[part 1 of 2: package /AUTOSAR_Dem/SwComponentTypes]
AUTOSAR XML (schema 4-2-2)
package /AUTOSAR_Dem/SwComponentTypes
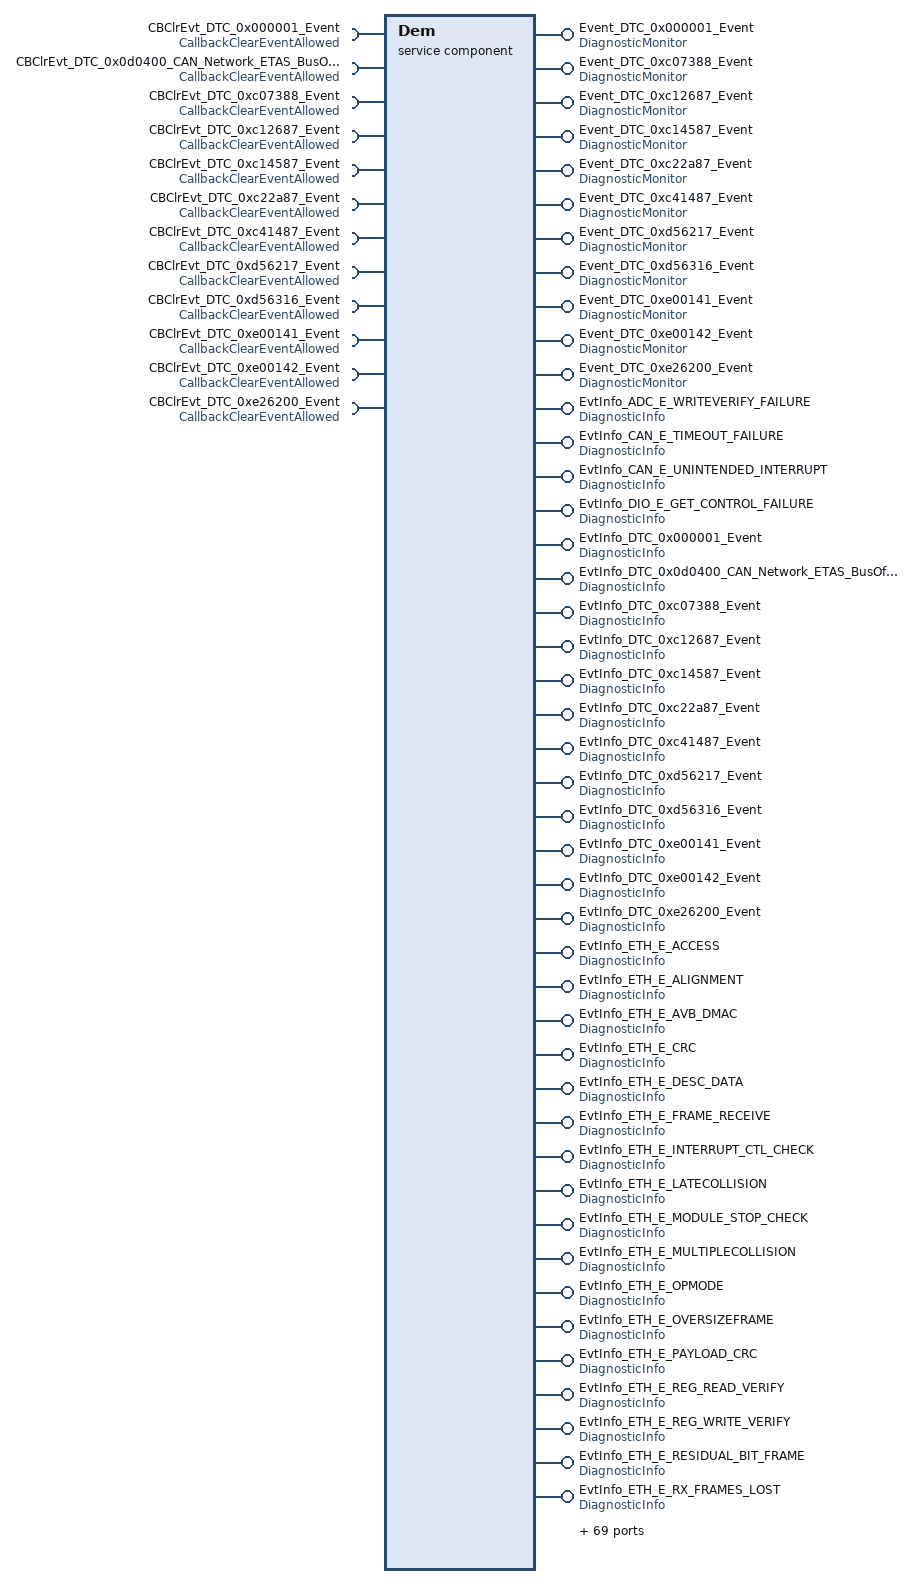
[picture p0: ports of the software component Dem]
  service sw component type Dem
    113 x provide port:
      Event_DTC_0x000001_Event: provided-interface=DiagnosticMonitor
        provided-com-specs:
          operation=SetEventStatus, queue-length=1
          operation=SetEventStatusWithEnvdata, queue-length=1
          operation=ResetEventStatus, queue-length=1
          operation=PrestoreFreezeFrame, queue-length=1
          operation=ClearPrestoredFreezeFrame, queue-length=1
          operation=ResetEventDebounceStatus, queue-length=1
      Event_DTC_0xc07388_Event: provided-interface=DiagnosticMonitor
        provided-com-specs:
          operation=SetEventStatus, queue-length=1
          operation=SetEventStatusWithEnvdata, queue-length=1
          operation=ResetEventStatus, queue-length=1
          operation=PrestoreFreezeFrame, queue-length=1
          operation=ClearPrestoredFreezeFrame, queue-length=1
          operation=ResetEventDebounceStatus, queue-length=1
      Event_DTC_0xc12687_Event: provided-interface=DiagnosticMonitor
        provided-com-specs:
          operation=SetEventStatus, queue-length=1
          operation=SetEventStatusWithEnvdata, queue-length=1
          operation=ResetEventStatus, queue-length=1
          operation=PrestoreFreezeFrame, queue-length=1
          operation=ClearPrestoredFreezeFrame, queue-length=1
          operation=ResetEventDebounceStatus, queue-length=1
      Event_DTC_0xc14587_Event: provided-interface=DiagnosticMonitor
        provided-com-specs:
          operation=SetEventStatus, queue-length=1
          operation=SetEventStatusWithEnvdata, queue-length=1
          operation=ResetEventStatus, queue-length=1
          operation=PrestoreFreezeFrame, queue-length=1
          operation=ClearPrestoredFreezeFrame, queue-length=1
          operation=ResetEventDebounceStatus, queue-length=1
      Event_DTC_0xc22a87_Event: provided-interface=DiagnosticMonitor
        provided-com-specs:
          operation=SetEventStatus, queue-length=1
          operation=SetEventStatusWithEnvdata, queue-length=1
          operation=ResetEventStatus, queue-length=1
          operation=PrestoreFreezeFrame, queue-length=1
          operation=ClearPrestoredFreezeFrame, queue-length=1
          operation=ResetEventDebounceStatus, queue-length=1
      Event_DTC_0xc41487_Event: provided-interface=DiagnosticMonitor
        provided-com-specs:
          operation=SetEventStatus, queue-length=1
          operation=SetEventStatusWithEnvdata, queue-length=1
          operation=ResetEventStatus, queue-length=1
          operation=PrestoreFreezeFrame, queue-length=1
          operation=ClearPrestoredFreezeFrame, queue-length=1
          operation=ResetEventDebounceStatus, queue-length=1
      Event_DTC_0xd56217_Event: provided-interface=DiagnosticMonitor
        provided-com-specs:
          operation=SetEventStatus, queue-length=1
          operation=SetEventStatusWithEnvdata, queue-length=1
          operation=ResetEventStatus, queue-length=1
          operation=PrestoreFreezeFrame, queue-length=1
          operation=ClearPrestoredFreezeFrame, queue-length=1
          operation=ResetEventDebounceStatus, queue-length=1
      Event_DTC_0xd56316_Event: provided-interface=DiagnosticMonitor
        provided-com-specs:
          operation=SetEventStatus, queue-length=1
          operation=SetEventStatusWithEnvdata, queue-length=1
          operation=ResetEventStatus, queue-length=1
          operation=PrestoreFreezeFrame, queue-length=1
          operation=ClearPrestoredFreezeFrame, queue-length=1
          operation=ResetEventDebounceStatus, queue-length=1
      Event_DTC_0xe00141_Event: provided-interface=DiagnosticMonitor
        provided-com-specs:
          operation=SetEventStatus, queue-length=1
          operation=SetEventStatusWithEnvdata, queue-length=1
          operation=ResetEventStatus, queue-length=1
          operation=PrestoreFreezeFrame, queue-length=1
          operation=ClearPrestoredFreezeFrame, queue-length=1
          operation=ResetEventDebounceStatus, queue-length=1
      Event_DTC_0xe00142_Event: provided-interface=DiagnosticMonitor
        provided-com-specs:
          operation=SetEventStatus, queue-length=1
          operation=SetEventStatusWithEnvdata, queue-length=1
          operation=ResetEventStatus, queue-length=1
          operation=PrestoreFreezeFrame, queue-length=1
          operation=ClearPrestoredFreezeFrame, queue-length=1
          operation=ResetEventDebounceStatus, queue-length=1
      Event_DTC_0xe26200_Event: provided-interface=DiagnosticMonitor
        provided-com-specs:
          operation=SetEventStatus, queue-length=1
          operation=SetEventStatusWithEnvdata, queue-length=1
          operation=ResetEventStatus, queue-length=1
          operation=PrestoreFreezeFrame, queue-length=1
          operation=ClearPrestoredFreezeFrame, queue-length=1
          operation=ResetEventDebounceStatus, queue-length=1
      EvtInfo_ADC_E_WRITEVERIFY_FAILURE: provided-interface=DiagnosticInfo
        provided-com-specs:
          operation=DiagnosticInfo/GetEventStatus, queue-length=1
          operation=DiagnosticInfo/GetEventFailed, queue-length=1
          operation=DiagnosticInfo/GetEventTested, queue-length=1
          operation=DiagnosticInfo/GetDTCOfEvent, queue-length=1
          operation=DiagnosticInfo/GetDebouncingOfEvent, queue-length=1
          operation=DiagnosticInfo/GetFaultDetectionCounter, queue-length=1
          operation=DiagnosticInfo/GetEventExtendedDataRecord, queue-length=1
          operation=DiagnosticInfo/GetEventExtendedDataRecordEx, queue-length=1
          operation=DiagnosticInfo/GetEventFreezeFrameData, queue-length=1
          operation=DiagnosticInfo/GetEventFreezeFrameDataEx, queue-length=1
      EvtInfo_CAN_E_TIMEOUT_FAILURE: provided-interface=DiagnosticInfo
        provided-com-specs:
          operation=DiagnosticInfo/GetEventStatus, queue-length=1
          operation=DiagnosticInfo/GetEventFailed, queue-length=1
          operation=DiagnosticInfo/GetEventTested, queue-length=1
          operation=DiagnosticInfo/GetDTCOfEvent, queue-length=1
          operation=DiagnosticInfo/GetDebouncingOfEvent, queue-length=1
          operation=DiagnosticInfo/GetFaultDetectionCounter, queue-length=1
          operation=DiagnosticInfo/GetEventExtendedDataRecord, queue-length=1
          operation=DiagnosticInfo/GetEventExtendedDataRecordEx, queue-length=1
          operation=DiagnosticInfo/GetEventFreezeFrameData, queue-length=1
          operation=DiagnosticInfo/GetEventFreezeFrameDataEx, queue-length=1
      EvtInfo_CAN_E_UNINTENDED_INTERRUPT: provided-interface=DiagnosticInfo
        provided-com-specs:
          operation=DiagnosticInfo/GetEventStatus, queue-length=1
          operation=DiagnosticInfo/GetEventFailed, queue-length=1
          operation=DiagnosticInfo/GetEventTested, queue-length=1
          operation=DiagnosticInfo/GetDTCOfEvent, queue-length=1
          operation=DiagnosticInfo/GetDebouncingOfEvent, queue-length=1
          operation=DiagnosticInfo/GetFaultDetectionCounter, queue-length=1
          operation=DiagnosticInfo/GetEventExtendedDataRecord, queue-length=1
          operation=DiagnosticInfo/GetEventExtendedDataRecordEx, queue-length=1
          operation=DiagnosticInfo/GetEventFreezeFrameData, queue-length=1
          operation=DiagnosticInfo/GetEventFreezeFrameDataEx, queue-length=1
      EvtInfo_DIO_E_GET_CONTROL_FAILURE: provided-interface=DiagnosticInfo
        provided-com-specs:
          operation=DiagnosticInfo/GetEventStatus, queue-length=1
          operation=DiagnosticInfo/GetEventFailed, queue-length=1
          operation=DiagnosticInfo/GetEventTested, queue-length=1
          operation=DiagnosticInfo/GetDTCOfEvent, queue-length=1
          operation=DiagnosticInfo/GetDebouncingOfEvent, queue-length=1
          operation=DiagnosticInfo/GetFaultDetectionCounter, queue-length=1
          operation=DiagnosticInfo/GetEventExtendedDataRecord, queue-length=1
          operation=DiagnosticInfo/GetEventExtendedDataRecordEx, queue-length=1
          operation=DiagnosticInfo/GetEventFreezeFrameData, queue-length=1
          operation=DiagnosticInfo/GetEventFreezeFrameDataEx, queue-length=1
      EvtInfo_DTC_0x000001_Event: provided-interface=DiagnosticInfo
        provided-com-specs:
          operation=DiagnosticInfo/GetEventStatus, queue-length=1
          operation=DiagnosticInfo/GetEventFailed, queue-length=1
          operation=DiagnosticInfo/GetEventTested, queue-length=1
          operation=DiagnosticInfo/GetDTCOfEvent, queue-length=1
          operation=DiagnosticInfo/GetDebouncingOfEvent, queue-length=1
          operation=DiagnosticInfo/GetFaultDetectionCounter, queue-length=1
          operation=DiagnosticInfo/GetEventExtendedDataRecord, queue-length=1
          operation=DiagnosticInfo/GetEventExtendedDataRecordEx, queue-length=1
          operation=DiagnosticInfo/GetEventFreezeFrameData, queue-length=1
          operation=DiagnosticInfo/GetEventFreezeFrameDataEx, queue-length=1
      EvtInfo_DTC_0x0d0400_CAN_Network_ETAS_BusOff_Event: provided-interface=DiagnosticInfo
        provided-com-specs:
          operation=DiagnosticInfo/GetEventStatus, queue-length=1
          operation=DiagnosticInfo/GetEventFailed, queue-length=1
          operation=DiagnosticInfo/GetEventTested, queue-length=1
          operation=DiagnosticInfo/GetDTCOfEvent, queue-length=1
          operation=DiagnosticInfo/GetDebouncingOfEvent, queue-length=1
          operation=DiagnosticInfo/GetFaultDetectionCounter, queue-length=1
          operation=DiagnosticInfo/GetEventExtendedDataRecord, queue-length=1
          operation=DiagnosticInfo/GetEventExtendedDataRecordEx, queue-length=1
          operation=DiagnosticInfo/GetEventFreezeFrameData, queue-length=1
          operation=DiagnosticInfo/GetEventFreezeFrameDataEx, queue-length=1
      EvtInfo_DTC_0xc07388_Event: provided-interface=DiagnosticInfo
        provided-com-specs:
          operation=DiagnosticInfo/GetEventStatus, queue-length=1
          operation=DiagnosticInfo/GetEventFailed, queue-length=1
          operation=DiagnosticInfo/GetEventTested, queue-length=1
          operation=DiagnosticInfo/GetDTCOfEvent, queue-length=1
          operation=DiagnosticInfo/GetDebouncingOfEvent, queue-length=1
          operation=DiagnosticInfo/GetFaultDetectionCounter, queue-length=1
          operation=DiagnosticInfo/GetEventExtendedDataRecord, queue-length=1
          operation=DiagnosticInfo/GetEventExtendedDataRecordEx, queue-length=1
          operation=DiagnosticInfo/GetEventFreezeFrameData, queue-length=1
          operation=DiagnosticInfo/GetEventFreezeFrameDataEx, queue-length=1
      EvtInfo_DTC_0xc12687_Event: provided-interface=DiagnosticInfo
        provided-com-specs:
          operation=DiagnosticInfo/GetEventStatus, queue-length=1
          operation=DiagnosticInfo/GetEventFailed, queue-length=1
          operation=DiagnosticInfo/GetEventTested, queue-length=1
          operation=DiagnosticInfo/GetDTCOfEvent, queue-length=1
          operation=DiagnosticInfo/GetDebouncingOfEvent, queue-length=1
          operation=DiagnosticInfo/GetFaultDetectionCounter, queue-length=1
          operation=DiagnosticInfo/GetEventExtendedDataRecord, queue-length=1
          operation=DiagnosticInfo/GetEventExtendedDataRecordEx, queue-length=1
          operation=DiagnosticInfo/GetEventFreezeFrameData, queue-length=1
          operation=DiagnosticInfo/GetEventFreezeFrameDataEx, queue-length=1
      EvtInfo_DTC_0xc14587_Event: provided-interface=DiagnosticInfo
        provided-com-specs:
          operation=DiagnosticInfo/GetEventStatus, queue-length=1
          operation=DiagnosticInfo/GetEventFailed, queue-length=1
          operation=DiagnosticInfo/GetEventTested, queue-length=1
          operation=DiagnosticInfo/GetDTCOfEvent, queue-length=1
          operation=DiagnosticInfo/GetDebouncingOfEvent, queue-length=1
          operation=DiagnosticInfo/GetFaultDetectionCounter, queue-length=1
          operation=DiagnosticInfo/GetEventExtendedDataRecord, queue-length=1
          operation=DiagnosticInfo/GetEventExtendedDataRecordEx, queue-length=1
          operation=DiagnosticInfo/GetEventFreezeFrameData, queue-length=1
          operation=DiagnosticInfo/GetEventFreezeFrameDataEx, queue-length=1
      EvtInfo_DTC_0xc22a87_Event: provided-interface=DiagnosticInfo
        provided-com-specs:
          operation=DiagnosticInfo/GetEventStatus, queue-length=1
          operation=DiagnosticInfo/GetEventFailed, queue-length=1
          operation=DiagnosticInfo/GetEventTested, queue-length=1
          operation=DiagnosticInfo/GetDTCOfEvent, queue-length=1
          operation=DiagnosticInfo/GetDebouncingOfEvent, queue-length=1
          operation=DiagnosticInfo/GetFaultDetectionCounter, queue-length=1
          operation=DiagnosticInfo/GetEventExtendedDataRecord, queue-length=1
          operation=DiagnosticInfo/GetEventExtendedDataRecordEx, queue-length=1
          operation=DiagnosticInfo/GetEventFreezeFrameData, queue-length=1
          operation=DiagnosticInfo/GetEventFreezeFrameDataEx, queue-length=1
      EvtInfo_DTC_0xc41487_Event: provided-interface=DiagnosticInfo
        provided-com-specs:
          operation=DiagnosticInfo/GetEventStatus, queue-length=1
          operation=DiagnosticInfo/GetEventFailed, queue-length=1
          operation=DiagnosticInfo/GetEventTested, queue-length=1
          operation=DiagnosticInfo/GetDTCOfEvent, queue-length=1
          operation=DiagnosticInfo/GetDebouncingOfEvent, queue-length=1
          operation=DiagnosticInfo/GetFaultDetectionCounter, queue-length=1
          operation=DiagnosticInfo/GetEventExtendedDataRecord, queue-length=1
          operation=DiagnosticInfo/GetEventExtendedDataRecordEx, queue-length=1
          operation=DiagnosticInfo/GetEventFreezeFrameData, queue-length=1
          operation=DiagnosticInfo/GetEventFreezeFrameDataEx, queue-length=1
      EvtInfo_DTC_0xd56217_Event: provided-interface=DiagnosticInfo
        provided-com-specs:
          operation=DiagnosticInfo/GetEventStatus, queue-length=1
          operation=DiagnosticInfo/GetEventFailed, queue-length=1
          operation=DiagnosticInfo/GetEventTested, queue-length=1
          operation=DiagnosticInfo/GetDTCOfEvent, queue-length=1
          operation=DiagnosticInfo/GetDebouncingOfEvent, queue-length=1
          operation=DiagnosticInfo/GetFaultDetectionCounter, queue-length=1
          operation=DiagnosticInfo/GetEventExtendedDataRecord, queue-length=1
          operation=DiagnosticInfo/GetEventExtendedDataRecordEx, queue-length=1
          operation=DiagnosticInfo/GetEventFreezeFrameData, queue-length=1
          operation=DiagnosticInfo/GetEventFreezeFrameDataEx, queue-length=1
      EvtInfo_DTC_0xd56316_Event: provided-interface=DiagnosticInfo
        provided-com-specs:
          operation=DiagnosticInfo/GetEventStatus, queue-length=1
          operation=DiagnosticInfo/GetEventFailed, queue-length=1
          operation=DiagnosticInfo/GetEventTested, queue-length=1
          operation=DiagnosticInfo/GetDTCOfEvent, queue-length=1
          operation=DiagnosticInfo/GetDebouncingOfEvent, queue-length=1
          operation=DiagnosticInfo/GetFaultDetectionCounter, queue-length=1
          operation=DiagnosticInfo/GetEventExtendedDataRecord, queue-length=1
          operation=DiagnosticInfo/GetEventExtendedDataRecordEx, queue-length=1
          operation=DiagnosticInfo/GetEventFreezeFrameData, queue-length=1
          operation=DiagnosticInfo/GetEventFreezeFrameDataEx, queue-length=1
      EvtInfo_DTC_0xe00141_Event: provided-interface=DiagnosticInfo
        provided-com-specs:
          operation=DiagnosticInfo/GetEventStatus, queue-length=1
          operation=DiagnosticInfo/GetEventFailed, queue-length=1
          operation=DiagnosticInfo/GetEventTested, queue-length=1
          operation=DiagnosticInfo/GetDTCOfEvent, queue-length=1
          operation=DiagnosticInfo/GetDebouncingOfEvent, queue-length=1
          operation=DiagnosticInfo/GetFaultDetectionCounter, queue-length=1
          operation=DiagnosticInfo/GetEventExtendedDataRecord, queue-length=1
          operation=DiagnosticInfo/GetEventExtendedDataRecordEx, queue-length=1
          operation=DiagnosticInfo/GetEventFreezeFrameData, queue-length=1
          operation=DiagnosticInfo/GetEventFreezeFrameDataEx, queue-length=1
      EvtInfo_DTC_0xe00142_Event: provided-interface=DiagnosticInfo
        provided-com-specs:
          operation=DiagnosticInfo/GetEventStatus, queue-length=1
          operation=DiagnosticInfo/GetEventFailed, queue-length=1
          operation=DiagnosticInfo/GetEventTested, queue-length=1
          operation=DiagnosticInfo/GetDTCOfEvent, queue-length=1
          operation=DiagnosticInfo/GetDebouncingOfEvent, queue-length=1
          operation=DiagnosticInfo/GetFaultDetectionCounter, queue-length=1
          operation=DiagnosticInfo/GetEventExtendedDataRecord, queue-length=1
          operation=DiagnosticInfo/GetEventExtendedDataRecordEx, queue-length=1
          operation=DiagnosticInfo/GetEventFreezeFrameData, queue-length=1
          operation=DiagnosticInfo/GetEventFreezeFrameDataEx, queue-length=1
      EvtInfo_DTC_0xe26200_Event: provided-interface=DiagnosticInfo
        provided-com-specs:
          operation=DiagnosticInfo/GetEventStatus, queue-length=1
          operation=DiagnosticInfo/GetEventFailed, queue-length=1
          operation=DiagnosticInfo/GetEventTested, queue-length=1
          operation=DiagnosticInfo/GetDTCOfEvent, queue-length=1
          operation=DiagnosticInfo/GetDebouncingOfEvent, queue-length=1
          operation=DiagnosticInfo/GetFaultDetectionCounter, queue-length=1
          operation=DiagnosticInfo/GetEventExtendedDataRecord, queue-length=1
          operation=DiagnosticInfo/GetEventExtendedDataRecordEx, queue-length=1
          operation=DiagnosticInfo/GetEventFreezeFrameData, queue-length=1
          operation=DiagnosticInfo/GetEventFreezeFrameDataEx, queue-length=1
      EvtInfo_ETH_E_ACCESS: provided-interface=DiagnosticInfo
        provided-com-specs:
          operation=DiagnosticInfo/GetEventStatus, queue-length=1
          operation=DiagnosticInfo/GetEventFailed, queue-length=1
          operation=DiagnosticInfo/GetEventTested, queue-length=1
          operation=DiagnosticInfo/GetDTCOfEvent, queue-length=1
          operation=DiagnosticInfo/GetDebouncingOfEvent, queue-length=1
          operation=DiagnosticInfo/GetFaultDetectionCounter, queue-length=1
          operation=DiagnosticInfo/GetEventExtendedDataRecord, queue-length=1
          operation=DiagnosticInfo/GetEventExtendedDataRecordEx, queue-length=1
          operation=DiagnosticInfo/GetEventFreezeFrameData, queue-length=1
          operation=DiagnosticInfo/GetEventFreezeFrameDataEx, queue-length=1
      EvtInfo_ETH_E_ALIGNMENT: provided-interface=DiagnosticInfo
        provided-com-specs:
          operation=DiagnosticInfo/GetEventStatus, queue-length=1
          operation=DiagnosticInfo/GetEventFailed, queue-length=1
          operation=DiagnosticInfo/GetEventTested, queue-length=1
          operation=DiagnosticInfo/GetDTCOfEvent, queue-length=1
          operation=DiagnosticInfo/GetDebouncingOfEvent, queue-length=1
          operation=DiagnosticInfo/GetFaultDetectionCounter, queue-length=1
          operation=DiagnosticInfo/GetEventExtendedDataRecord, queue-length=1
          operation=DiagnosticInfo/GetEventExtendedDataRecordEx, queue-length=1
          operation=DiagnosticInfo/GetEventFreezeFrameData, queue-length=1
          operation=DiagnosticInfo/GetEventFreezeFrameDataEx, queue-length=1
      EvtInfo_ETH_E_AVB_DMAC: provided-interface=DiagnosticInfo
        provided-com-specs:
          operation=DiagnosticInfo/GetEventStatus, queue-length=1
          operation=DiagnosticInfo/GetEventFailed, queue-length=1
          operation=DiagnosticInfo/GetEventTested, queue-length=1
          operation=DiagnosticInfo/GetDTCOfEvent, queue-length=1
          operation=DiagnosticInfo/GetDebouncingOfEvent, queue-length=1
          operation=DiagnosticInfo/GetFaultDetectionCounter, queue-length=1
          operation=DiagnosticInfo/GetEventExtendedDataRecord, queue-length=1
          operation=DiagnosticInfo/GetEventExtendedDataRecordEx, queue-length=1
          operation=DiagnosticInfo/GetEventFreezeFrameData, queue-length=1
          operation=DiagnosticInfo/GetEventFreezeFrameDataEx, queue-length=1
      EvtInfo_ETH_E_CRC: provided-interface=DiagnosticInfo
        provided-com-specs:
          operation=DiagnosticInfo/GetEventStatus, queue-length=1
          operation=DiagnosticInfo/GetEventFailed, queue-length=1
          operation=DiagnosticInfo/GetEventTested, queue-length=1
          operation=DiagnosticInfo/GetDTCOfEvent, queue-length=1
          operation=DiagnosticInfo/GetDebouncingOfEvent, queue-length=1
          operation=DiagnosticInfo/GetFaultDetectionCounter, queue-length=1
          operation=DiagnosticInfo/GetEventExtendedDataRecord, queue-length=1
          operation=DiagnosticInfo/GetEventExtendedDataRecordEx, queue-length=1
          operation=DiagnosticInfo/GetEventFreezeFrameData, queue-length=1
          operation=DiagnosticInfo/GetEventFreezeFrameDataEx, queue-length=1
      EvtInfo_ETH_E_DESC_DATA: provided-interface=DiagnosticInfo
        provided-com-specs:
          operation=DiagnosticInfo/GetEventStatus, queue-length=1
          operation=DiagnosticInfo/GetEventFailed, queue-length=1
          operation=DiagnosticInfo/GetEventTested, queue-length=1
          operation=DiagnosticInfo/GetDTCOfEvent, queue-length=1
          operation=DiagnosticInfo/GetDebouncingOfEvent, queue-length=1
          operation=DiagnosticInfo/GetFaultDetectionCounter, queue-length=1
          operation=DiagnosticInfo/GetEventExtendedDataRecord, queue-length=1
          operation=DiagnosticInfo/GetEventExtendedDataRecordEx, queue-length=1
          operation=DiagnosticInfo/GetEventFreezeFrameData, queue-length=1
          operation=DiagnosticInfo/GetEventFreezeFrameDataEx, queue-length=1
      EvtInfo_ETH_E_FRAME_RECEIVE: provided-interface=DiagnosticInfo
        provided-com-specs:
          operation=DiagnosticInfo/GetEventStatus, queue-length=1
          operation=DiagnosticInfo/GetEventFailed, queue-length=1
          operation=DiagnosticInfo/GetEventTested, queue-length=1
          operation=DiagnosticInfo/GetDTCOfEvent, queue-length=1
          operation=DiagnosticInfo/GetDebouncingOfEvent, queue-length=1
          operation=DiagnosticInfo/GetFaultDetectionCounter, queue-length=1
          operation=DiagnosticInfo/GetEventExtendedDataRecord, queue-length=1
          operation=DiagnosticInfo/GetEventExtendedDataRecordEx, queue-length=1
          operation=DiagnosticInfo/GetEventFreezeFrameData, queue-length=1
          operation=DiagnosticInfo/GetEventFreezeFrameDataEx, queue-length=1
      EvtInfo_ETH_E_INTERRUPT_CTL_CHECK: provided-interface=DiagnosticInfo
        provided-com-specs:
          operation=DiagnosticInfo/GetEventStatus, queue-length=1
          operation=DiagnosticInfo/GetEventFailed, queue-length=1
          operation=DiagnosticInfo/GetEventTested, queue-length=1
          operation=DiagnosticInfo/GetDTCOfEvent, queue-length=1
          operation=DiagnosticInfo/GetDebouncingOfEvent, queue-length=1
          operation=DiagnosticInfo/GetFaultDetectionCounter, queue-length=1
          operation=DiagnosticInfo/GetEventExtendedDataRecord, queue-length=1
          operation=DiagnosticInfo/GetEventExtendedDataRecordEx, queue-length=1
          operation=DiagnosticInfo/GetEventFreezeFrameData, queue-length=1
          operation=DiagnosticInfo/GetEventFreezeFrameDataEx, queue-length=1
      EvtInfo_ETH_E_LATECOLLISION: provided-interface=DiagnosticInfo
        provided-com-specs:
          operation=DiagnosticInfo/GetEventStatus, queue-length=1
          operation=DiagnosticInfo/GetEventFailed, queue-length=1
          operation=DiagnosticInfo/GetEventTested, queue-length=1
          operation=DiagnosticInfo/GetDTCOfEvent, queue-length=1
          operation=DiagnosticInfo/GetDebouncingOfEvent, queue-length=1
          operation=DiagnosticInfo/GetFaultDetectionCounter, queue-length=1
          operation=DiagnosticInfo/GetEventExtendedDataRecord, queue-length=1
          operation=DiagnosticInfo/GetEventExtendedDataRecordEx, queue-length=1
          operation=DiagnosticInfo/GetEventFreezeFrameData, queue-length=1
          operation=DiagnosticInfo/GetEventFreezeFrameDataEx, queue-length=1
      EvtInfo_ETH_E_MODULE_STOP_CHECK: provided-interface=DiagnosticInfo
        provided-com-specs:
          operation=DiagnosticInfo/GetEventStatus, queue-length=1
          operation=DiagnosticInfo/GetEventFailed, queue-length=1
          operation=DiagnosticInfo/GetEventTested, queue-length=1
          operation=DiagnosticInfo/GetDTCOfEvent, queue-length=1
          operation=DiagnosticInfo/GetDebouncingOfEvent, queue-length=1
          operation=DiagnosticInfo/GetFaultDetectionCounter, queue-length=1
          operation=DiagnosticInfo/GetEventExtendedDataRecord, queue-length=1
          operation=DiagnosticInfo/GetEventExtendedDataRecordEx, queue-length=1
          operation=DiagnosticInfo/GetEventFreezeFrameData, queue-length=1
          operation=DiagnosticInfo/GetEventFreezeFrameDataEx, queue-length=1
      EvtInfo_ETH_E_MULTIPLECOLLISION: provided-interface=DiagnosticInfo
        provided-com-specs:
          operation=DiagnosticInfo/GetEventStatus, queue-length=1
          operation=DiagnosticInfo/GetEventFailed, queue-length=1
          operation=DiagnosticInfo/GetEventTested, queue-length=1
          operation=DiagnosticInfo/GetDTCOfEvent, queue-length=1
          operation=DiagnosticInfo/GetDebouncingOfEvent, queue-length=1
          operation=DiagnosticInfo/GetFaultDetectionCounter, queue-length=1
          operation=DiagnosticInfo/GetEventExtendedDataRecord, queue-length=1
          operation=DiagnosticInfo/GetEventExtendedDataRecordEx, queue-length=1
          operation=DiagnosticInfo/GetEventFreezeFrameData, queue-length=1
          operation=DiagnosticInfo/GetEventFreezeFrameDataEx, queue-length=1
      EvtInfo_ETH_E_OPMODE: provided-interface=DiagnosticInfo
        provided-com-specs:
          operation=DiagnosticInfo/GetEventStatus, queue-length=1
          operation=DiagnosticInfo/GetEventFailed, queue-length=1
          operation=DiagnosticInfo/GetEventTested, queue-length=1
          operation=DiagnosticInfo/GetDTCOfEvent, queue-length=1
          operation=DiagnosticInfo/GetDebouncingOfEvent, queue-length=1
          operation=DiagnosticInfo/GetFaultDetectionCounter, queue-length=1
          operation=DiagnosticInfo/GetEventExtendedDataRecord, queue-length=1
          operation=DiagnosticInfo/GetEventExtendedDataRecordEx, queue-length=1
          operation=DiagnosticInfo/GetEventFreezeFrameData, queue-length=1
          operation=DiagnosticInfo/GetEventFreezeFrameDataEx, queue-length=1
      EvtInfo_ETH_E_OVERSIZEFRAME: provided-interface=DiagnosticInfo
        provided-com-specs:
          operation=DiagnosticInfo/GetEventStatus, queue-length=1
          operation=DiagnosticInfo/GetEventFailed, queue-length=1
          operation=DiagnosticInfo/GetEventTested, queue-length=1
          operation=DiagnosticInfo/GetDTCOfEvent, queue-length=1
          operation=DiagnosticInfo/GetDebouncingOfEvent, queue-length=1
          operation=DiagnosticInfo/GetFaultDetectionCounter, queue-length=1
          operation=DiagnosticInfo/GetEventExtendedDataRecord, queue-length=1
          operation=DiagnosticInfo/GetEventExtendedDataRecordEx, queue-length=1
          operation=DiagnosticInfo/GetEventFreezeFrameData, queue-length=1
          operation=DiagnosticInfo/GetEventFreezeFrameDataEx, queue-length=1
      EvtInfo_ETH_E_PAYLOAD_CRC: provided-interface=DiagnosticInfo
        provided-com-specs:
          operation=DiagnosticInfo/GetEventStatus, queue-length=1
          operation=DiagnosticInfo/GetEventFailed, queue-length=1
          operation=DiagnosticInfo/GetEventTested, queue-length=1
          operation=DiagnosticInfo/GetDTCOfEvent, queue-length=1
          operation=DiagnosticInfo/GetDebouncingOfEvent, queue-length=1
          operation=DiagnosticInfo/GetFaultDetectionCounter, queue-length=1
          operation=DiagnosticInfo/GetEventExtendedDataRecord, queue-length=1
          operation=DiagnosticInfo/GetEventExtendedDataRecordEx, queue-length=1
          operation=DiagnosticInfo/GetEventFreezeFrameData, queue-length=1
          operation=DiagnosticInfo/GetEventFreezeFrameDataEx, queue-length=1
      EvtInfo_ETH_E_REG_READ_VERIFY: provided-interface=DiagnosticInfo
        provided-com-specs:
          operation=DiagnosticInfo/GetEventStatus, queue-length=1
          operation=DiagnosticInfo/GetEventFailed, queue-length=1
          operation=DiagnosticInfo/GetEventTested, queue-length=1
          operation=DiagnosticInfo/GetDTCOfEvent, queue-length=1
          operation=DiagnosticInfo/GetDebouncingOfEvent, queue-length=1
          operation=DiagnosticInfo/GetFaultDetectionCounter, queue-length=1
          operation=DiagnosticInfo/GetEventExtendedDataRecord, queue-length=1
          operation=DiagnosticInfo/GetEventExtendedDataRecordEx, queue-length=1
          operation=DiagnosticInfo/GetEventFreezeFrameData, queue-length=1
          operation=DiagnosticInfo/GetEventFreezeFrameDataEx, queue-length=1
      EvtInfo_ETH_E_REG_WRITE_VERIFY: provided-interface=DiagnosticInfo
        provided-com-specs:
          operation=DiagnosticInfo/GetEventStatus, queue-length=1
          operation=DiagnosticInfo/GetEventFailed, queue-length=1
          operation=DiagnosticInfo/GetEventTested, queue-length=1
          operation=DiagnosticInfo/GetDTCOfEvent, queue-length=1
          operation=DiagnosticInfo/GetDebouncingOfEvent, queue-length=1
          operation=DiagnosticInfo/GetFaultDetectionCounter, queue-length=1
          operation=DiagnosticInfo/GetEventExtendedDataRecord, queue-length=1
          operation=DiagnosticInfo/GetEventExtendedDataRecordEx, queue-length=1
          operation=DiagnosticInfo/GetEventFreezeFrameData, queue-length=1
          operation=DiagnosticInfo/GetEventFreezeFrameDataEx, queue-length=1
      EvtInfo_ETH_E_RESIDUAL_BIT_FRAME: provided-interface=DiagnosticInfo
        provided-com-specs:
          operation=DiagnosticInfo/GetEventStatus, queue-length=1
          operation=DiagnosticInfo/GetEventFailed, queue-length=1
          operation=DiagnosticInfo/GetEventTested, queue-length=1
          operation=DiagnosticInfo/GetDTCOfEvent, queue-length=1
          operation=DiagnosticInfo/GetDebouncingOfEvent, queue-length=1
          operation=DiagnosticInfo/GetFaultDetectionCounter, queue-length=1
          operation=DiagnosticInfo/GetEventExtendedDataRecord, queue-length=1
          operation=DiagnosticInfo/GetEventExtendedDataRecordEx, queue-length=1
          operation=DiagnosticInfo/GetEventFreezeFrameData, queue-length=1
          operation=DiagnosticInfo/GetEventFreezeFrameDataEx, queue-length=1
      EvtInfo_ETH_E_RX_FRAMES_LOST: provided-interface=DiagnosticInfo
        provided-com-specs:
          operation=DiagnosticInfo/GetEventStatus, queue-length=1
          operation=DiagnosticInfo/GetEventFailed, queue-length=1
          operation=DiagnosticInfo/GetEventTested, queue-length=1
          operation=DiagnosticInfo/GetDTCOfEvent, queue-length=1
          operation=DiagnosticInfo/GetDebouncingOfEvent, queue-length=1
          operation=DiagnosticInfo/GetFaultDetectionCounter, queue-length=1
          operation=DiagnosticInfo/GetEventExtendedDataRecord, queue-length=1
          operation=DiagnosticInfo/GetEventExtendedDataRecordEx, queue-length=1
          operation=DiagnosticInfo/GetEventFreezeFrameData, queue-length=1
          operation=DiagnosticInfo/GetEventFreezeFrameDataEx, queue-length=1
      EvtInfo_ETH_E_SINGLECOLLISION: provided-interface=DiagnosticInfo
        provided-com-specs:
          operation=DiagnosticInfo/GetEventStatus, queue-length=1
          operation=DiagnosticInfo/GetEventFailed, queue-length=1
          operation=DiagnosticInfo/GetEventTested, queue-length=1
          operation=DiagnosticInfo/GetDTCOfEvent, queue-length=1
          operation=DiagnosticInfo/GetDebouncingOfEvent, queue-length=1
          operation=DiagnosticInfo/GetFaultDetectionCounter, queue-length=1
          operation=DiagnosticInfo/GetEventExtendedDataRecord, queue-length=1
          operation=DiagnosticInfo/GetEventExtendedDataRecordEx, queue-length=1
          operation=DiagnosticInfo/GetEventFreezeFrameData, queue-length=1
          operation=DiagnosticInfo/GetEventFreezeFrameDataEx, queue-length=1
      EvtInfo_ETH_E_TIMEOUT: provided-interface=DiagnosticInfo
        provided-com-specs:
          operation=DiagnosticInfo/GetEventStatus, queue-length=1
          operation=DiagnosticInfo/GetEventFailed, queue-length=1
          operation=DiagnosticInfo/GetEventTested, queue-length=1
          operation=DiagnosticInfo/GetDTCOfEvent, queue-length=1
          operation=DiagnosticInfo/GetDebouncingOfEvent, queue-length=1
          operation=DiagnosticInfo/GetFaultDetectionCounter, queue-length=1
          operation=DiagnosticInfo/GetEventExtendedDataRecord, queue-length=1
          operation=DiagnosticInfo/GetEventExtendedDataRecordEx, queue-length=1
          operation=DiagnosticInfo/GetEventFreezeFrameData, queue-length=1
          operation=DiagnosticInfo/GetEventFreezeFrameDataEx, queue-length=1
      EvtInfo_ETH_E_TIMERINC_FAILED: provided-interface=DiagnosticInfo
        provided-com-specs:
          operation=DiagnosticInfo/GetEventStatus, queue-length=1
          operation=DiagnosticInfo/GetEventFailed, queue-length=1
          operation=DiagnosticInfo/GetEventTested, queue-length=1
          operation=DiagnosticInfo/GetDTCOfEvent, queue-length=1
          operation=DiagnosticInfo/GetDebouncingOfEvent, queue-length=1
          operation=DiagnosticInfo/GetFaultDetectionCounter, queue-length=1
          operation=DiagnosticInfo/GetEventExtendedDataRecord, queue-length=1
          operation=DiagnosticInfo/GetEventExtendedDataRecordEx, queue-length=1
          operation=DiagnosticInfo/GetEventFreezeFrameData, queue-length=1
          operation=DiagnosticInfo/GetEventFreezeFrameDataEx, queue-length=1
      EvtInfo_ETH_E_TRANSMIT_RETRY_OVER: provided-interface=DiagnosticInfo
        provided-com-specs:
          operation=DiagnosticInfo/GetEventStatus, queue-length=1
          operation=DiagnosticInfo/GetEventFailed, queue-length=1
          operation=DiagnosticInfo/GetEventTested, queue-length=1
          operation=DiagnosticInfo/GetDTCOfEvent, queue-length=1
          operation=DiagnosticInfo/GetDebouncingOfEvent, queue-length=1
          operation=DiagnosticInfo/GetFaultDetectionCounter, queue-length=1
          operation=DiagnosticInfo/GetEventExtendedDataRecord, queue-length=1
          operation=DiagnosticInfo/GetEventExtendedDataRecordEx, queue-length=1
          operation=DiagnosticInfo/GetEventFreezeFrameData, queue-length=1
          operation=DiagnosticInfo/GetEventFreezeFrameDataEx, queue-length=1
      EvtInfo_ETH_E_UNDERSIZEFRAME: provided-interface=DiagnosticInfo
        provided-com-specs:
          operation=DiagnosticInfo/GetEventStatus, queue-length=1
          operation=DiagnosticInfo/GetEventFailed, queue-length=1
          operation=DiagnosticInfo/GetEventTested, queue-length=1
          operation=DiagnosticInfo/GetDTCOfEvent, queue-length=1
          operation=DiagnosticInfo/GetDebouncingOfEvent, queue-length=1
          operation=DiagnosticInfo/GetFaultDetectionCounter, queue-length=1
          operation=DiagnosticInfo/GetEventExtendedDataRecord, queue-length=1
          operation=DiagnosticInfo/GetEventExtendedDataRecordEx, queue-length=1
          operation=DiagnosticInfo/GetEventFreezeFrameData, queue-length=1
          operation=DiagnosticInfo/GetEventFreezeFrameDataEx, queue-length=1
      EvtInfo_FLS_E_COMPARE_FAILED: provided-interface=DiagnosticInfo
        provided-com-specs:
          operation=DiagnosticInfo/GetEventStatus, queue-length=1
          operation=DiagnosticInfo/GetEventFailed, queue-length=1
          operation=DiagnosticInfo/GetEventTested, queue-length=1
          operation=DiagnosticInfo/GetDTCOfEvent, queue-length=1
          operation=DiagnosticInfo/GetDebouncingOfEvent, queue-length=1
          operation=DiagnosticInfo/GetFaultDetectionCounter, queue-length=1
          operation=DiagnosticInfo/GetEventExtendedDataRecord, queue-length=1
          operation=DiagnosticInfo/GetEventExtendedDataRecordEx, queue-length=1
          operation=DiagnosticInfo/GetEventFreezeFrameData, queue-length=1
          operation=DiagnosticInfo/GetEventFreezeFrameDataEx, queue-length=1
      EvtInfo_FLS_E_ERASE_FAILED: provided-interface=DiagnosticInfo
        provided-com-specs:
          operation=DiagnosticInfo/GetEventStatus, queue-length=1
          operation=DiagnosticInfo/GetEventFailed, queue-length=1
          operation=DiagnosticInfo/GetEventTested, queue-length=1
          operation=DiagnosticInfo/GetDTCOfEvent, queue-length=1
          operation=DiagnosticInfo/GetDebouncingOfEvent, queue-length=1
          operation=DiagnosticInfo/GetFaultDetectionCounter, queue-length=1
          operation=DiagnosticInfo/GetEventExtendedDataRecord, queue-length=1
          operation=DiagnosticInfo/GetEventExtendedDataRecordEx, queue-length=1
          operation=DiagnosticInfo/GetEventFreezeFrameData, queue-length=1
          operation=DiagnosticInfo/GetEventFreezeFrameDataEx, queue-length=1
      EvtInfo_FLS_E_GET_CONTROL_FAILURE: provided-interface=DiagnosticInfo
        provided-com-specs:
          operation=DiagnosticInfo/GetEventStatus, queue-length=1
          operation=DiagnosticInfo/GetEventFailed, queue-length=1
          operation=DiagnosticInfo/GetEventTested, queue-length=1
          operation=DiagnosticInfo/GetDTCOfEvent, queue-length=1
          operation=DiagnosticInfo/GetDebouncingOfEvent, queue-length=1
          operation=DiagnosticInfo/GetFaultDetectionCounter, queue-length=1
          operation=DiagnosticInfo/GetEventExtendedDataRecord, queue-length=1
          operation=DiagnosticInfo/GetEventExtendedDataRecordEx, queue-length=1
          operation=DiagnosticInfo/GetEventFreezeFrameData, queue-length=1
          operation=DiagnosticInfo/GetEventFreezeFrameDataEx, queue-length=1
      EvtInfo_FLS_E_GET_SEMAPHORE_FAILURE: provided-interface=DiagnosticInfo
        provided-com-specs:
          operation=DiagnosticInfo/GetEventStatus, queue-length=1
          operation=DiagnosticInfo/GetEventFailed, queue-length=1
          operation=DiagnosticInfo/GetEventTested, queue-length=1
          operation=DiagnosticInfo/GetDTCOfEvent, queue-length=1
          operation=DiagnosticInfo/GetDebouncingOfEvent, queue-length=1
          operation=DiagnosticInfo/GetFaultDetectionCounter, queue-length=1
          operation=DiagnosticInfo/GetEventExtendedDataRecord, queue-length=1
          operation=DiagnosticInfo/GetEventExtendedDataRecordEx, queue-length=1
          operation=DiagnosticInfo/GetEventFreezeFrameData, queue-length=1
          operation=DiagnosticInfo/GetEventFreezeFrameDataEx, queue-length=1
      EvtInfo_FLS_E_READ_FAILED: provided-interface=DiagnosticInfo
        provided-com-specs:
          operation=DiagnosticInfo/GetEventStatus, queue-length=1
          operation=DiagnosticInfo/GetEventFailed, queue-length=1
          operation=DiagnosticInfo/GetEventTested, queue-length=1
          operation=DiagnosticInfo/GetDTCOfEvent, queue-length=1
          operation=DiagnosticInfo/GetDebouncingOfEvent, queue-length=1
          operation=DiagnosticInfo/GetFaultDetectionCounter, queue-length=1
          operation=DiagnosticInfo/GetEventExtendedDataRecord, queue-length=1
          operation=DiagnosticInfo/GetEventExtendedDataRecordEx, queue-length=1
          operation=DiagnosticInfo/GetEventFreezeFrameData, queue-length=1
          operation=DiagnosticInfo/GetEventFreezeFrameDataEx, queue-length=1
      EvtInfo_FLS_E_RELEASE_SEMAPHORE_FAILURE: provided-interface=DiagnosticInfo
        provided-com-specs:
          operation=DiagnosticInfo/GetEventStatus, queue-length=1
          operation=DiagnosticInfo/GetEventFailed, queue-length=1
          operation=DiagnosticInfo/GetEventTested, queue-length=1
          operation=DiagnosticInfo/GetDTCOfEvent, queue-length=1
          operation=DiagnosticInfo/GetDebouncingOfEvent, queue-length=1
          operation=DiagnosticInfo/GetFaultDetectionCounter, queue-length=1
          operation=DiagnosticInfo/GetEventExtendedDataRecord, queue-length=1
          operation=DiagnosticInfo/GetEventExtendedDataRecordEx, queue-length=1
          operation=DiagnosticInfo/GetEventFreezeFrameData, queue-length=1
          operation=DiagnosticInfo/GetEventFreezeFrameDataEx, queue-length=1
      EvtInfo_FLS_E_UNEXPECTED_FLASH_ID: provided-interface=DiagnosticInfo
        provided-com-specs:
          operation=DiagnosticInfo/GetEventStatus, queue-length=1
          operation=DiagnosticInfo/GetEventFailed, queue-length=1
          operation=DiagnosticInfo/GetEventTested, queue-length=1
          operation=DiagnosticInfo/GetDTCOfEvent, queue-length=1
          operation=DiagnosticInfo/GetDebouncingOfEvent, queue-length=1
          operation=DiagnosticInfo/GetFaultDetectionCounter, queue-length=1
          operation=DiagnosticInfo/GetEventExtendedDataRecord, queue-length=1
          operation=DiagnosticInfo/GetEventExtendedDataRecordEx, queue-length=1
          operation=DiagnosticInfo/GetEventFreezeFrameData, queue-length=1
          operation=DiagnosticInfo/GetEventFreezeFrameDataEx, queue-length=1
      EvtInfo_FLS_E_WRITE_FAILED: provided-interface=DiagnosticInfo
        provided-com-specs:
          operation=DiagnosticInfo/GetEventStatus, queue-length=1
          operation=DiagnosticInfo/GetEventFailed, queue-length=1
          operation=DiagnosticInfo/GetEventTested, queue-length=1
          operation=DiagnosticInfo/GetDTCOfEvent, queue-length=1
          operation=DiagnosticInfo/GetDebouncingOfEvent, queue-length=1
          operation=DiagnosticInfo/GetFaultDetectionCounter, queue-length=1
          operation=DiagnosticInfo/GetEventExtendedDataRecord, queue-length=1
          operation=DiagnosticInfo/GetEventExtendedDataRecordEx, queue-length=1
          operation=DiagnosticInfo/GetEventFreezeFrameData, queue-length=1
          operation=DiagnosticInfo/GetEventFreezeFrameDataEx, queue-length=1
      EvtInfo_FLS_E_WRITE_VERIFY_FAILURE: provided-interface=DiagnosticInfo
        provided-com-specs:
          operation=DiagnosticInfo/GetEventStatus, queue-length=1
          operation=DiagnosticInfo/GetEventFailed, queue-length=1
          operation=DiagnosticInfo/GetEventTested, queue-length=1
          operation=DiagnosticInfo/GetDTCOfEvent, queue-length=1
          operation=DiagnosticInfo/GetDebouncingOfEvent, queue-length=1
          operation=DiagnosticInfo/GetFaultDetectionCounter, queue-length=1
          operation=DiagnosticInfo/GetEventExtendedDataRecord, queue-length=1
          operation=DiagnosticInfo/GetEventExtendedDataRecordEx, queue-length=1
          operation=DiagnosticInfo/GetEventFreezeFrameData, queue-length=1
          operation=DiagnosticInfo/GetEventFreezeFrameDataEx, queue-length=1
      EvtInfo_GPT_E_CONFIGURATION_CHECK_PERMANENT_FAILURE: provided-interface=DiagnosticInfo
        provided-com-specs:
          operation=DiagnosticInfo/GetEventStatus, queue-length=1
          operation=DiagnosticInfo/GetEventFailed, queue-length=1
          operation=DiagnosticInfo/GetEventTested, queue-length=1
          operation=DiagnosticInfo/GetDTCOfEvent, queue-length=1
          operation=DiagnosticInfo/GetDebouncingOfEvent, queue-length=1
          operation=DiagnosticInfo/GetFaultDetectionCounter, queue-length=1
          operation=DiagnosticInfo/GetEventExtendedDataRecord, queue-length=1
          operation=DiagnosticInfo/GetEventExtendedDataRecordEx, queue-length=1
          operation=DiagnosticInfo/GetEventFreezeFrameData, queue-length=1
          operation=DiagnosticInfo/GetEventFreezeFrameDataEx, queue-length=1
      EvtInfo_GPT_E_CONFIGURATION_CHECK_TRANSIENT_FAILURE: provided-interface=DiagnosticInfo
        provided-com-specs:
          operation=DiagnosticInfo/GetEventStatus, queue-length=1
          operation=DiagnosticInfo/GetEventFailed, queue-length=1
          operation=DiagnosticInfo/GetEventTested, queue-length=1
          operation=DiagnosticInfo/GetDTCOfEvent, queue-length=1
          operation=DiagnosticInfo/GetDebouncingOfEvent, queue-length=1
          operation=DiagnosticInfo/GetFaultDetectionCounter, queue-length=1
          operation=DiagnosticInfo/GetEventExtendedDataRecord, queue-length=1
          operation=DiagnosticInfo/GetEventExtendedDataRecordEx, queue-length=1
          operation=DiagnosticInfo/GetEventFreezeFrameData, queue-length=1
          operation=DiagnosticInfo/GetEventFreezeFrameDataEx, queue-length=1
      EvtInfo_GPT_E_INTERRUPT_CONTROLLER_FAILURE: provided-interface=DiagnosticInfo
        provided-com-specs:
          operation=DiagnosticInfo/GetEventStatus, queue-length=1
          operation=DiagnosticInfo/GetEventFailed, queue-length=1
          operation=DiagnosticInfo/GetEventTested, queue-length=1
          operation=DiagnosticInfo/GetDTCOfEvent, queue-length=1
          operation=DiagnosticInfo/GetDebouncingOfEvent, queue-length=1
          operation=DiagnosticInfo/GetFaultDetectionCounter, queue-length=1
          operation=DiagnosticInfo/GetEventExtendedDataRecord, queue-length=1
          operation=DiagnosticInfo/GetEventExtendedDataRecordEx, queue-length=1
          operation=DiagnosticInfo/GetEventFreezeFrameData, queue-length=1
          operation=DiagnosticInfo/GetEventFreezeFrameDataEx, queue-length=1
      EvtInfo_GPT_E_WRITEVERIFY_FAILURE: provided-interface=DiagnosticInfo
        provided-com-specs:
          operation=DiagnosticInfo/GetEventStatus, queue-length=1
          operation=DiagnosticInfo/GetEventFailed, queue-length=1
          operation=DiagnosticInfo/GetEventTested, queue-length=1
          operation=DiagnosticInfo/GetDTCOfEvent, queue-length=1
          operation=DiagnosticInfo/GetDebouncingOfEvent, queue-length=1
          operation=DiagnosticInfo/GetFaultDetectionCounter, queue-length=1
          operation=DiagnosticInfo/GetEventExtendedDataRecord, queue-length=1
          operation=DiagnosticInfo/GetEventExtendedDataRecordEx, queue-length=1
          operation=DiagnosticInfo/GetEventFreezeFrameData, queue-length=1
          operation=DiagnosticInfo/GetEventFreezeFrameDataEx, queue-length=1
      EvtInfo_MCU_E_CHECK_FAILURE: provided-interface=DiagnosticInfo
        provided-com-specs:
          operation=DiagnosticInfo/GetEventStatus, queue-length=1
          operation=DiagnosticInfo/GetEventFailed, queue-length=1
          operation=DiagnosticInfo/GetEventTested, queue-length=1
          operation=DiagnosticInfo/GetDTCOfEvent, queue-length=1
          operation=DiagnosticInfo/GetDebouncingOfEvent, queue-length=1
          operation=DiagnosticInfo/GetFaultDetectionCounter, queue-length=1
          operation=DiagnosticInfo/GetEventExtendedDataRecord, queue-length=1
          operation=DiagnosticInfo/GetEventExtendedDataRecordEx, queue-length=1
          operation=DiagnosticInfo/GetEventFreezeFrameData, queue-length=1
          operation=DiagnosticInfo/GetEventFreezeFrameDataEx, queue-length=1
      EvtInfo_MCU_E_CLOCK_FAILURE: provided-interface=DiagnosticInfo
        provided-com-specs:
          operation=DiagnosticInfo/GetEventStatus, queue-length=1
          operation=DiagnosticInfo/GetEventFailed, queue-length=1
          operation=DiagnosticInfo/GetEventTested, queue-length=1
          operation=DiagnosticInfo/GetDTCOfEvent, queue-length=1
          operation=DiagnosticInfo/GetDebouncingOfEvent, queue-length=1
          operation=DiagnosticInfo/GetFaultDetectionCounter, queue-length=1
          operation=DiagnosticInfo/GetEventExtendedDataRecord, queue-length=1
          operation=DiagnosticInfo/GetEventExtendedDataRecordEx, queue-length=1
          operation=DiagnosticInfo/GetEventFreezeFrameData, queue-length=1
          operation=DiagnosticInfo/GetEventFreezeFrameDataEx, queue-length=1
      EvtInfo_MCU_E_CONFIGURATION_CHECK_PERMANENT_FAILURE: provided-interface=DiagnosticInfo
        provided-com-specs:
          operation=DiagnosticInfo/GetEventStatus, queue-length=1
          operation=DiagnosticInfo/GetEventFailed, queue-length=1
          operation=DiagnosticInfo/GetEventTested, queue-length=1
          operation=DiagnosticInfo/GetDTCOfEvent, queue-length=1
          operation=DiagnosticInfo/GetDebouncingOfEvent, queue-length=1
          operation=DiagnosticInfo/GetFaultDetectionCounter, queue-length=1
          operation=DiagnosticInfo/GetEventExtendedDataRecord, queue-length=1
          operation=DiagnosticInfo/GetEventExtendedDataRecordEx, queue-length=1
          operation=DiagnosticInfo/GetEventFreezeFrameData, queue-length=1
          operation=DiagnosticInfo/GetEventFreezeFrameDataEx, queue-length=1
      EvtInfo_MCU_E_CONFIGURATION_CHECK_TRANSIENT_FAILURE: provided-interface=DiagnosticInfo
        provided-com-specs:
          operation=DiagnosticInfo/GetEventStatus, queue-length=1
          operation=DiagnosticInfo/GetEventFailed, queue-length=1
          operation=DiagnosticInfo/GetEventTested, queue-length=1
          operation=DiagnosticInfo/GetDTCOfEvent, queue-length=1
          operation=DiagnosticInfo/GetDebouncingOfEvent, queue-length=1
          operation=DiagnosticInfo/GetFaultDetectionCounter, queue-length=1
          operation=DiagnosticInfo/GetEventExtendedDataRecord, queue-length=1
          operation=DiagnosticInfo/GetEventExtendedDataRecordEx, queue-length=1
          operation=DiagnosticInfo/GetEventFreezeFrameData, queue-length=1
          operation=DiagnosticInfo/GetEventFreezeFrameDataEx, queue-length=1
      EvtInfo_MCU_E_CONFIGURATION_CHECK_TRANSITION_FAILURE: provided-interface=DiagnosticInfo
        provided-com-specs:
          operation=DiagnosticInfo/GetEventStatus, queue-length=1
          operation=DiagnosticInfo/GetEventFailed, queue-length=1
          operation=DiagnosticInfo/GetEventTested, queue-length=1
          operation=DiagnosticInfo/GetDTCOfEvent, queue-length=1
          operation=DiagnosticInfo/GetDebouncingOfEvent, queue-length=1
          operation=DiagnosticInfo/GetFaultDetectionCounter, queue-length=1
          operation=DiagnosticInfo/GetEventExtendedDataRecord, queue-length=1
          operation=DiagnosticInfo/GetEventExtendedDataRecordEx, queue-length=1
          operation=DiagnosticInfo/GetEventFreezeFrameData, queue-length=1
          operation=DiagnosticInfo/GetEventFreezeFrameDataEx, queue-length=1
      EvtInfo_MCU_E_GET_CONTROL_FAILURE: provided-interface=DiagnosticInfo
        provided-com-specs:
          operation=DiagnosticInfo/GetEventStatus, queue-length=1
          operation=DiagnosticInfo/GetEventFailed, queue-length=1
          operation=DiagnosticInfo/GetEventTested, queue-length=1
          operation=DiagnosticInfo/GetDTCOfEvent, queue-length=1
          operation=DiagnosticInfo/GetDebouncingOfEvent, queue-length=1
          operation=DiagnosticInfo/GetFaultDetectionCounter, queue-length=1
          operation=DiagnosticInfo/GetEventExtendedDataRecord, queue-length=1
          operation=DiagnosticInfo/GetEventExtendedDataRecordEx, queue-length=1
          operation=DiagnosticInfo/GetEventFreezeFrameData, queue-length=1
          operation=DiagnosticInfo/GetEventFreezeFrameDataEx, queue-length=1
      EvtInfo_MCU_E_INTERNAL_BUS_FAILURE: provided-interface=DiagnosticInfo
        provided-com-specs:
          operation=DiagnosticInfo/GetEventStatus, queue-length=1
          operation=DiagnosticInfo/GetEventFailed, queue-length=1
          operation=DiagnosticInfo/GetEventTested, queue-length=1
          operation=DiagnosticInfo/GetDTCOfEvent, queue-length=1
          operation=DiagnosticInfo/GetDebouncingOfEvent, queue-length=1
          operation=DiagnosticInfo/GetFaultDetectionCounter, queue-length=1
          operation=DiagnosticInfo/GetEventExtendedDataRecord, queue-length=1
          operation=DiagnosticInfo/GetEventExtendedDataRecordEx, queue-length=1
          operation=DiagnosticInfo/GetEventFreezeFrameData, queue-length=1
          operation=DiagnosticInfo/GetEventFreezeFrameDataEx, queue-length=1
      EvtInfo_MCU_E_READ_BACK_FAILURE: provided-interface=DiagnosticInfo
        provided-com-specs:
          operation=DiagnosticInfo/GetEventStatus, queue-length=1
          operation=DiagnosticInfo/GetEventFailed, queue-length=1
          operation=DiagnosticInfo/GetEventTested, queue-length=1
          operation=DiagnosticInfo/GetDTCOfEvent, queue-length=1
          operation=DiagnosticInfo/GetDebouncingOfEvent, queue-length=1
          operation=DiagnosticInfo/GetFaultDetectionCounter, queue-length=1
          operation=DiagnosticInfo/GetEventExtendedDataRecord, queue-length=1
          operation=DiagnosticInfo/GetEventExtendedDataRecordEx, queue-length=1
          operation=DiagnosticInfo/GetEventFreezeFrameData, queue-length=1
          operation=DiagnosticInfo/GetEventFreezeFrameDataEx, queue-length=1
      EvtInfo_MCU_E_TIMEOUT_FAILURE: provided-interface=DiagnosticInfo
        provided-com-specs:
          operation=DiagnosticInfo/GetEventStatus, queue-length=1
          operation=DiagnosticInfo/GetEventFailed, queue-length=1
          operation=DiagnosticInfo/GetEventTested, queue-length=1
          operation=DiagnosticInfo/GetDTCOfEvent, queue-length=1
          operation=DiagnosticInfo/GetDebouncingOfEvent, queue-length=1
          operation=DiagnosticInfo/GetFaultDetectionCounter, queue-length=1
          operation=DiagnosticInfo/GetEventExtendedDataRecord, queue-length=1
          operation=DiagnosticInfo/GetEventExtendedDataRecordEx, queue-length=1
          operation=DiagnosticInfo/GetEventFreezeFrameData, queue-length=1
          operation=DiagnosticInfo/GetEventFreezeFrameDataEx, queue-length=1
      EvtInfo_MCU_E_WRITE_TIMEOUT_FAILURE: provided-interface=DiagnosticInfo
        provided-com-specs:
          operation=DiagnosticInfo/GetEventStatus, queue-length=1
          operation=DiagnosticInfo/GetEventFailed, queue-length=1
          operation=DiagnosticInfo/GetEventTested, queue-length=1
          operation=DiagnosticInfo/GetDTCOfEvent, queue-length=1
          operation=DiagnosticInfo/GetDebouncingOfEvent, queue-length=1
          operation=DiagnosticInfo/GetFaultDetectionCounter, queue-length=1
          operation=DiagnosticInfo/GetEventExtendedDataRecord, queue-length=1
          operation=DiagnosticInfo/GetEventExtendedDataRecordEx, queue-length=1
          operation=DiagnosticInfo/GetEventFreezeFrameData, queue-length=1
          operation=DiagnosticInfo/GetEventFreezeFrameDataEx, queue-length=1
      EvtInfo_PORT_E_CONFIGURATION_CHECK_PERMANENT_FAILURE: provided-interface=DiagnosticInfo
        provided-com-specs:
          operation=DiagnosticInfo/GetEventStatus, queue-length=1
          operation=DiagnosticInfo/GetEventFailed, queue-length=1
          operation=DiagnosticInfo/GetEventTested, queue-length=1
          operation=DiagnosticInfo/GetDTCOfEvent, queue-length=1
          operation=DiagnosticInfo/GetDebouncingOfEvent, queue-length=1
          operation=DiagnosticInfo/GetFaultDetectionCounter, queue-length=1
          operation=DiagnosticInfo/GetEventExtendedDataRecord, queue-length=1
          operation=DiagnosticInfo/GetEventExtendedDataRecordEx, queue-length=1
          operation=DiagnosticInfo/GetEventFreezeFrameData, queue-length=1
          operation=DiagnosticInfo/GetEventFreezeFrameDataEx, queue-length=1
      EvtInfo_PORT_E_CONFIGURATION_CHECK_TRANSIENT_FAILURE: provided-interface=DiagnosticInfo
        provided-com-specs:
          operation=DiagnosticInfo/GetEventStatus, queue-length=1
          operation=DiagnosticInfo/GetEventFailed, queue-length=1
          operation=DiagnosticInfo/GetEventTested, queue-length=1
          operation=DiagnosticInfo/GetDTCOfEvent, queue-length=1
          operation=DiagnosticInfo/GetDebouncingOfEvent, queue-length=1
          operation=DiagnosticInfo/GetFaultDetectionCounter, queue-length=1
          operation=DiagnosticInfo/GetEventExtendedDataRecord, queue-length=1
          operation=DiagnosticInfo/GetEventExtendedDataRecordEx, queue-length=1
          operation=DiagnosticInfo/GetEventFreezeFrameData, queue-length=1
          operation=DiagnosticInfo/GetEventFreezeFrameDataEx, queue-length=1
      EvtInfo_PORT_E_FUSE_MONITORING_FAILURE: provided-interface=DiagnosticInfo
        provided-com-specs:
          operation=DiagnosticInfo/GetEventStatus, queue-length=1
          operation=DiagnosticInfo/GetEventFailed, queue-length=1
          operation=DiagnosticInfo/GetEventTested, queue-length=1
          operation=DiagnosticInfo/GetDTCOfEvent, queue-length=1
          operation=DiagnosticInfo/GetDebouncingOfEvent, queue-length=1
          operation=DiagnosticInfo/GetFaultDetectionCounter, queue-length=1
          operation=DiagnosticInfo/GetEventExtendedDataRecord, queue-length=1
          operation=DiagnosticInfo/GetEventExtendedDataRecordEx, queue-length=1
          operation=DiagnosticInfo/GetEventFreezeFrameData, queue-length=1
          operation=DiagnosticInfo/GetEventFreezeFrameDataEx, queue-length=1
      EvtInfo_PORT_E_GET_CONTROL_FAILURE: provided-interface=DiagnosticInfo
        provided-com-specs:
          operation=DiagnosticInfo/GetEventStatus, queue-length=1
          operation=DiagnosticInfo/GetEventFailed, queue-length=1
          operation=DiagnosticInfo/GetEventTested, queue-length=1
          operation=DiagnosticInfo/GetDTCOfEvent, queue-length=1
          operation=DiagnosticInfo/GetDebouncingOfEvent, queue-length=1
          operation=DiagnosticInfo/GetFaultDetectionCounter, queue-length=1
          operation=DiagnosticInfo/GetEventExtendedDataRecord, queue-length=1
          operation=DiagnosticInfo/GetEventExtendedDataRecordEx, queue-length=1
          operation=DiagnosticInfo/GetEventFreezeFrameData, queue-length=1
          operation=DiagnosticInfo/GetEventFreezeFrameDataEx, queue-length=1
      EvtInfo_PORT_E_WRITE_VERIFY_FAILURE: provided-interface=DiagnosticInfo
        provided-com-specs:
          operation=DiagnosticInfo/GetEventStatus, queue-length=1
          operation=DiagnosticInfo/GetEventFailed, queue-length=1
          operation=DiagnosticInfo/GetEventTested, queue-length=1
          operation=DiagnosticInfo/GetDTCOfEvent, queue-length=1
          operation=DiagnosticInfo/GetDebouncingOfEvent, queue-length=1
          operation=DiagnosticInfo/GetFaultDetectionCounter, queue-length=1
          operation=DiagnosticInfo/GetEventExtendedDataRecord, queue-length=1
          operation=DiagnosticInfo/GetEventExtendedDataRecordEx, queue-length=1
          operation=DiagnosticInfo/GetEventFreezeFrameData, queue-length=1
          operation=DiagnosticInfo/GetEventFreezeFrameDataEx, queue-length=1
      EvtInfo_SPI_E_DATA_TX_TIMEOUT_FAILURE: provided-interface=DiagnosticInfo
        provided-com-specs:
          operation=DiagnosticInfo/GetEventStatus, queue-length=1
          operation=DiagnosticInfo/GetEventFailed, queue-length=1
          operation=DiagnosticInfo/GetEventTested, queue-length=1
          operation=DiagnosticInfo/GetDTCOfEvent, queue-length=1
          operation=DiagnosticInfo/GetDebouncingOfEvent, queue-length=1
          operation=DiagnosticInfo/GetFaultDetectionCounter, queue-length=1
          operation=DiagnosticInfo/GetEventExtendedDataRecord, queue-length=1
          operation=DiagnosticInfo/GetEventExtendedDataRecordEx, queue-length=1
          operation=DiagnosticInfo/GetEventFreezeFrameData, queue-length=1
          operation=DiagnosticInfo/GetEventFreezeFrameDataEx, queue-length=1
      EvtInfo_SPI_E_HARDWARE_ERROR: provided-interface=DiagnosticInfo
        provided-com-specs:
          operation=DiagnosticInfo/GetEventStatus, queue-length=1
          operation=DiagnosticInfo/GetEventFailed, queue-length=1
          operation=DiagnosticInfo/GetEventTested, queue-length=1
          operation=DiagnosticInfo/GetDTCOfEvent, queue-length=1
          operation=DiagnosticInfo/GetDebouncingOfEvent, queue-length=1
          operation=DiagnosticInfo/GetFaultDetectionCounter, queue-length=1
          operation=DiagnosticInfo/GetEventExtendedDataRecord, queue-length=1
          operation=DiagnosticInfo/GetEventExtendedDataRecordEx, queue-length=1
          operation=DiagnosticInfo/GetEventFreezeFrameData, queue-length=1
          operation=DiagnosticInfo/GetEventFreezeFrameDataEx, queue-length=1
      EvtInfo_SPI_E_INTERRUPT_CONTROLLER_FAILURE: provided-interface=DiagnosticInfo
        provided-com-specs:
          operation=DiagnosticInfo/GetEventStatus, queue-length=1
          operation=DiagnosticInfo/GetEventFailed, queue-length=1
          operation=DiagnosticInfo/GetEventTested, queue-length=1
          operation=DiagnosticInfo/GetDTCOfEvent, queue-length=1
          operation=DiagnosticInfo/GetDebouncingOfEvent, queue-length=1
          operation=DiagnosticInfo/GetFaultDetectionCounter, queue-length=1
          operation=DiagnosticInfo/GetEventExtendedDataRecord, queue-length=1
          operation=DiagnosticInfo/GetEventExtendedDataRecordEx, queue-length=1
          operation=DiagnosticInfo/GetEventFreezeFrameData, queue-length=1
          operation=DiagnosticInfo/GetEventFreezeFrameDataEx, queue-length=1
      EvtInfo_SPI_E_UNINTENDED_EXECUTION_FAILURE: provided-interface=DiagnosticInfo
        provided-com-specs:
          operation=DiagnosticInfo/GetEventStatus, queue-length=1
          operation=DiagnosticInfo/GetEventFailed, queue-length=1
          operation=DiagnosticInfo/GetEventTested, queue-length=1
          operation=DiagnosticInfo/GetDTCOfEvent, queue-length=1
          operation=DiagnosticInfo/GetDebouncingOfEvent, queue-length=1
          operation=DiagnosticInfo/GetFaultDetectionCounter, queue-length=1
          operation=DiagnosticInfo/GetEventExtendedDataRecord, queue-length=1
          operation=DiagnosticInfo/GetEventExtendedDataRecordEx, queue-length=1
          operation=DiagnosticInfo/GetEventFreezeFrameData, queue-length=1
          operation=DiagnosticInfo/GetEventFreezeFrameDataEx, queue-length=1
      EvtInfo_SPI_E_UNINTENDED_MODULE_STOP_FAILURE: provided-interface=DiagnosticInfo
        provided-com-specs:
          operation=DiagnosticInfo/GetEventStatus, queue-length=1
          operation=DiagnosticInfo/GetEventFailed, queue-length=1
          operation=DiagnosticInfo/GetEventTested, queue-length=1
          operation=DiagnosticInfo/GetDTCOfEvent, queue-length=1
          operation=DiagnosticInfo/GetDebouncingOfEvent, queue-length=1
          operation=DiagnosticInfo/GetFaultDetectionCounter, queue-length=1
          operation=DiagnosticInfo/GetEventExtendedDataRecord, queue-length=1
          operation=DiagnosticInfo/GetEventExtendedDataRecordEx, queue-length=1
          operation=DiagnosticInfo/GetEventFreezeFrameData, queue-length=1
          operation=DiagnosticInfo/GetEventFreezeFrameDataEx, queue-length=1
      EvtInfo_SPI_E_WRITE_VERIFY_FAILURE: provided-interface=DiagnosticInfo
        provided-com-specs:
          operation=DiagnosticInfo/GetEventStatus, queue-length=1
          operation=DiagnosticInfo/GetEventFailed, queue-length=1
          operation=DiagnosticInfo/GetEventTested, queue-length=1
          operation=DiagnosticInfo/GetDTCOfEvent, queue-length=1
          operation=DiagnosticInfo/GetDebouncingOfEvent, queue-length=1
          operation=DiagnosticInfo/GetFaultDetectionCounter, queue-length=1
          operation=DiagnosticInfo/GetEventExtendedDataRecord, queue-length=1
          operation=DiagnosticInfo/GetEventExtendedDataRecordEx, queue-length=1
          operation=DiagnosticInfo/GetEventFreezeFrameData, queue-length=1
          operation=DiagnosticInfo/GetEventFreezeFrameDataEx, queue-length=1
      EvtInfo_WDG_E_DISABLE_REJECTED: provided-interface=DiagnosticInfo
        provided-com-specs:
          operation=DiagnosticInfo/GetEventStatus, queue-length=1
          operation=DiagnosticInfo/GetEventFailed, queue-length=1
          operation=DiagnosticInfo/GetEventTested, queue-length=1
          operation=DiagnosticInfo/GetDTCOfEvent, queue-length=1
          operation=DiagnosticInfo/GetDebouncingOfEvent, queue-length=1
          operation=DiagnosticInfo/GetFaultDetectionCounter, queue-length=1
          operation=DiagnosticInfo/GetEventExtendedDataRecord, queue-length=1
          operation=DiagnosticInfo/GetEventExtendedDataRecordEx, queue-length=1
          operation=DiagnosticInfo/GetEventFreezeFrameData, queue-length=1
          operation=DiagnosticInfo/GetEventFreezeFrameDataEx, queue-length=1
      EvtInfo_WDG_E_MODE_FAILED: provided-interface=DiagnosticInfo
        provided-com-specs:
          operation=DiagnosticInfo/GetEventStatus, queue-length=1
          operation=DiagnosticInfo/GetEventFailed, queue-length=1
          operation=DiagnosticInfo/GetEventTested, queue-length=1
          operation=DiagnosticInfo/GetDTCOfEvent, queue-length=1
          operation=DiagnosticInfo/GetDebouncingOfEvent, queue-length=1
          operation=DiagnosticInfo/GetFaultDetectionCounter, queue-length=1
          operation=DiagnosticInfo/GetEventExtendedDataRecord, queue-length=1
          operation=DiagnosticInfo/GetEventExtendedDataRecordEx, queue-length=1
          operation=DiagnosticInfo/GetEventFreezeFrameData, queue-length=1
          operation=DiagnosticInfo/GetEventFreezeFrameDataEx, queue-length=1
      EvtInfo_WDG_E_VALUE_COUNTER_FAILED: provided-interface=DiagnosticInfo
        provided-com-specs:
          operation=DiagnosticInfo/GetEventStatus, queue-length=1
          operation=DiagnosticInfo/GetEventFailed, queue-length=1
          operation=DiagnosticInfo/GetEventTested, queue-length=1
          operation=DiagnosticInfo/GetDTCOfEvent, queue-length=1
          operation=DiagnosticInfo/GetDebouncingOfEvent, queue-length=1
          operation=DiagnosticInfo/GetFaultDetectionCounter, queue-length=1
          operation=DiagnosticInfo/GetEventExtendedDataRecord, queue-length=1
          operation=DiagnosticInfo/GetEventExtendedDataRecordEx, queue-length=1
          operation=DiagnosticInfo/GetEventFreezeFrameData, queue-length=1
          operation=DiagnosticInfo/GetEventFreezeFrameDataEx, queue-length=1
      EvtInfo_WDG_E_WRITEVERIFY_FAILURE: provided-interface=DiagnosticInfo
        provided-com-specs:
          operation=DiagnosticInfo/GetEventStatus, queue-length=1
          operation=DiagnosticInfo/GetEventFailed, queue-length=1
          operation=DiagnosticInfo/GetEventTested, queue-length=1
          operation=DiagnosticInfo/GetDTCOfEvent, queue-length=1
          operation=DiagnosticInfo/GetDebouncingOfEvent, queue-length=1
          operation=DiagnosticInfo/GetFaultDetectionCounter, queue-length=1
          operation=DiagnosticInfo/GetEventExtendedDataRecord, queue-length=1
          operation=DiagnosticInfo/GetEventExtendedDataRecordEx, queue-length=1
          operation=DiagnosticInfo/GetEventFreezeFrameData, queue-length=1
          operation=DiagnosticInfo/GetEventFreezeFrameDataEx, queue-length=1
      EvtInfo_WDG_E_WRITE_REGISTER_FAILED: provided-interface=DiagnosticInfo
        provided-com-specs:
          operation=DiagnosticInfo/GetEventStatus, queue-length=1
          operation=DiagnosticInfo/GetEventFailed, queue-length=1
          operation=DiagnosticInfo/GetEventTested, queue-length=1
          operation=DiagnosticInfo/GetDTCOfEvent, queue-length=1
          operation=DiagnosticInfo/GetDebouncingOfEvent, queue-length=1
          operation=DiagnosticInfo/GetFaultDetectionCounter, queue-length=1
          operation=DiagnosticInfo/GetEventExtendedDataRecord, queue-length=1
          operation=DiagnosticInfo/GetEventExtendedDataRecordEx, queue-length=1
          operation=DiagnosticInfo/GetEventFreezeFrameData, queue-length=1
          operation=DiagnosticInfo/GetEventFreezeFrameDataEx, queue-length=1
      GeneralEvtInfo: provided-interface=GeneralDiagnosticInfo
        provided-com-specs:
          operation=GeneralDiagnosticInfo/GetEventStatus, queue-length=1
          operation=GeneralDiagnosticInfo/GetEventFailed, queue-length=1
          operation=GeneralDiagnosticInfo/GetEventTested, queue-length=1
          operation=GeneralDiagnosticInfo/GetDTCOfEvent, queue-length=1
          operation=GeneralDiagnosticInfo/GetDebouncingOfEvent, queue-length=1
          operation=GeneralDiagnosticInfo/GetFaultDetectionCounter, queue-length=1
          operation=GeneralDiagnosticInfo/GetEventExtendedDataRecord, queue-length=1
          operation=GeneralDiagnosticInfo/GetEventFreezeFrameData, queue-length=1
          operation=GeneralDiagnosticInfo/GetEventExtendedDataRecordEx, queue-length=1
          operation=GeneralDiagnosticInfo/GetEventFreezeFrameDataEx, queue-length=1
          operation=GetEventIdCausingLastDetError, queue-length=1
      OpCycle_DemOpCycle_DEM_POWER: provided-interface=OperationCycle
        provided-com-specs:
          operation=SetOperationCycleState, queue-length=1
          operation=GetOperationCycleState, queue-length=1
          operation=GetCycleQualified, queue-length=1
          operation=SetCycleQualified, queue-length=1
      StorageCond_DemStorageCondition: provided-com-specs=[{operation=SetStorageCondition, queue-length=1}, {operation=GetStorageCondition, queue-length=1}], provided-interface=StorageCondition
      ControlEventAvailable_DTC_0x000001_Event: server-com-spec{operation=SetEventAvailable, queue-length=1}, provided-interface=EventAvailable
      ControlEventAvailable_DTC_0xc07388_Event: server-com-spec{operation=SetEventAvailable, queue-length=1}, provided-interface=EventAvailable
      ControlEventAvailable_DTC_0xc12687_Event: server-com-spec{operation=SetEventAvailable, queue-length=1}, provided-interface=EventAvailable
      ControlEventAvailable_DTC_0xc14587_Event: server-com-spec{operation=SetEventAvailable, queue-length=1}, provided-interface=EventAvailable
      ControlEventAvailable_DTC_0xc22a87_Event: server-com-spec{operation=SetEventAvailable, queue-length=1}, provided-interface=EventAvailable
      ControlEventAvailable_DTC_0xc41487_Event: server-com-spec{operation=SetEventAvailable, queue-length=1}, provided-interface=EventAvailable
      ControlEventAvailable_DTC_0xd56217_Event: server-com-spec{operation=SetEventAvailable, queue-length=1}, provided-interface=EventAvailable
      ControlEventAvailable_DTC_0xd56316_Event: server-com-spec{operation=SetEventAvailable, queue-length=1}, provided-interface=EventAvailable
      ControlEventAvailable_DTC_0xe00141_Event: server-com-spec{operation=SetEventAvailable, queue-length=1}, provided-interface=EventAvailable
      ControlEventAvailable_DTC_0xe00142_Event: server-com-spec{operation=SetEventAvailable, queue-length=1}, provided-interface=EventAvailable
      ControlEventAvailable_DTC_0xe26200_Event: server-com-spec{operation=SetEventAvailable, queue-length=1}, provided-interface=EventAvailable
      EventStatus_DTC_0x000001_Event: server-com-spec{operation=SetWIRStatus, queue-length=1}, provided-interface=EventStatus
      EventStatus_DTC_0xc07388_Event: server-com-spec{operation=SetWIRStatus, queue-length=1}, provided-interface=EventStatus
      EventStatus_DTC_0xc12687_Event: server-com-spec{operation=SetWIRStatus, queue-length=1}, provided-interface=EventStatus
      EventStatus_DTC_0xc14587_Event: server-com-spec{operation=SetWIRStatus, queue-length=1}, provided-interface=EventStatus
      EventStatus_DTC_0xc22a87_Event: server-com-spec{operation=SetWIRStatus, queue-length=1}, provided-interface=EventStatus
      EventStatus_DTC_0xc41487_Event: server-com-spec{operation=SetWIRStatus, queue-length=1}, provided-interface=EventStatus
      EventStatus_DTC_0xd56217_Event: server-com-spec{operation=SetWIRStatus, queue-length=1}, provided-interface=EventStatus
      EventStatus_DTC_0xd56316_Event: server-com-spec{operation=SetWIRStatus, queue-length=1}, provided-interface=EventStatus
      EventStatus_DTC_0xe00141_Event: server-com-spec{operation=SetWIRStatus, queue-length=1}, provided-interface=EventStatus
      EventStatus_DTC_0xe00142_Event: server-com-spec{operation=SetWIRStatus, queue-length=1}, provided-interface=EventStatus
      EventStatus_DTC_0xe26200_Event: server-com-spec{operation=SetWIRStatus, queue-length=1}, provided-interface=EventStatus
    12 x require port, all with required-interface=CallbackClearEventAllowed:
      CBClrEvt_DTC_0x000001_Event
      CBClrEvt_DTC_0x0d0400_CAN_Network_ETAS_BusOff_Event
      CBClrEvt_DTC_0xc07388_Event
      CBClrEvt_DTC_0xc12687_Event
      CBClrEvt_DTC_0xc14587_Event
      CBClrEvt_DTC_0xc22a87_Event
      CBClrEvt_DTC_0xc41487_Event
      CBClrEvt_DTC_0xd56217_Event
      CBClrEvt_DTC_0xd56316_Event
      CBClrEvt_DTC_0xe00141_Event
      CBClrEvt_DTC_0xe00142_Event
      CBClrEvt_DTC_0xe26200_Event
